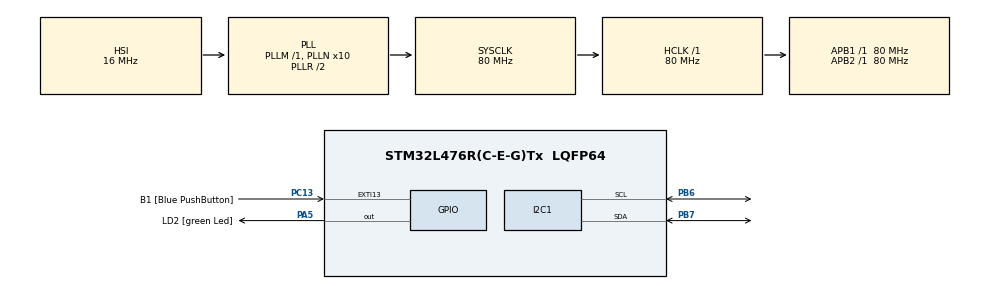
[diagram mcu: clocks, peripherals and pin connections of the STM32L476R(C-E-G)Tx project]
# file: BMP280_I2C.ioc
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I2C1.Timing=0x10D19CE4
Mcu.Family=STM32L4
Mcu.Name=STM32L476R(C-E-G)Tx
Mcu.Package=LQFP64
NVIC.PriorityGroup=NVIC_PRIORITYGROUP_4
PA13\ (JTMS-SWDIO).GPIO_Label=TMS
PA13\ (JTMS-SWDIO).Mode=Serial_Wire
PA13\ (JTMS-SWDIO).Signal=SYS_JTMS-SWDIO
PA14\ (JTCK-SWCLK).GPIO_Label=TCK
PA14\ (JTCK-SWCLK).Mode=Serial_Wire
PA14\ (JTCK-SWCLK).Signal=SYS_JTCK-SWCLK
PA5.GPIO_Label=LD2 [green Led]
PA5.GPIO_ModeDefaultOutputPP=GPIO_MODE_OUTPUT_PP
PA5.GPIO_PuPd=GPIO_NOPULL
PA5.GPIO_Speed=GPIO_SPEED_FREQ_LOW
PA5.Signal=GPIO_Output
PB3\ (JTDO-TRACESWO).GPIO_Label=SWO
PB3\ (JTDO-TRACESWO).Signal=SYS_JTDO-SWO
PB6.Mode=I2C
PB6.Signal=I2C1_SCL
PB7.Mode=I2C
PB7.Signal=I2C1_SDA
PC13.GPIO_Label=B1 [Blue PushButton]
PC13.GPIO_ModeDefaultEXTI=GPIO_MODE_IT_FALLING
PC13.GPIO_PuPd=GPIO_NOPULL
PC13.Signal=GPXTI13
PC14-OSC32_IN\ (PC14).Mode=LSE-External-Oscillator
PC14-OSC32_IN\ (PC14).Signal=RCC_OSC32_IN
PC15-OSC32_OUT\ (PC15).Mode=LSE-External-Oscillator
PC15-OSC32_OUT\ (PC15).Signal=RCC_OSC32_OUT
PH0-OSC_IN\ (PH0).Signal=RCC_OSC_IN
PH1-OSC_OUT\ (PH1).Signal=RCC_OSC_OUT
ProjectManager.HeapSize=0x200
ProjectManager.StackSize=0x400
ProjectManager.TargetToolchain=STM32CubeIDE
RCC.ADCFreq_Value=64000000
RCC.AHBFreq_Value=80000000
RCC.APB1Freq_Value=80000000
RCC.APB1TimFreq_Value=80000000
RCC.APB2Freq_Value=80000000
RCC.APB2TimFreq_Value=80000000
RCC.CortexFreq_Value=80000000
RCC.HCLKFreq_Value=80000000
RCC.HSE_VALUE=8000000
RCC.HSI_VALUE=16000000
RCC.MSI_VALUE=4000000
RCC.PLLN=10
RCC.PLLSourceVirtual=RCC_PLLSOURCE_HSI
RCC.PREFETCH_ENABLE=1
RCC.SYSCLKFreq_VALUE=80000000
RCC.SYSCLKSource=RCC_SYSCLKSOURCE_PLLCLK
RCC.USBFreq_Value=64000000
RCC.VCOOutputFreq_Value=160000000
board=NUCLEO-L476RG

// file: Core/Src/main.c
/* USER CODE BEGIN Header */
/**
  ******************************************************************************
  * @file           : main.c
  * @brief          : Main program body
  ******************************************************************************
  */
 /* USER CODE END Header */

#include "main.h"
#include "BMP280.h"

I2C_HandleTypeDef hi2c1;

void SystemClock_Config(void);
static void MX_GPIO_Init(void);
static void MX_I2C1_Init(void);

/* USER CODE BEGIN PV */
float temperature = 0.0f;
float pressure = 0.0f;
/* USER CODE END PV */

int main(void)
{
  HAL_Init();
  SystemClock_Config();

  MX_GPIO_Init();
  MX_I2C1_Init();

  /* USER CODE BEGIN 2 */
  if (BMP280_Config( BMP280_MODE_NORMAL, BMP280_OSRS_2, BMP280_OSRS_16, BMP280_T_SB_500, BMP280_FILTER_4) != 0)
  {
    Error_Handler(); // BMP280 init failed
  }
  /* USER CODE END 2 */

  while (1)
  {
    /* USER CODE BEGIN WHILE */
    if (BMP280_ReadSensor(&temperature, &pressure) == 0)
    {
        // temperature -> °C
        // pressure    -> hPa

        HAL_GPIO_TogglePin(LD2_GPIO_Port, LD2_Pin); // heartbeat LED
    }

    HAL_Delay(1000);
    /* USER CODE END WHILE */
  }
}

/* ======================= Peripheral Init ======================= */

void SystemClock_Config(void)
{
  RCC_OscInitTypeDef RCC_OscInitStruct = {0};
  RCC_ClkInitTypeDef RCC_ClkInitStruct = {0};

  HAL_PWREx_ControlVoltageScaling(PWR_REGULATOR_VOLTAGE_SCALE1);

  RCC_OscInitStruct.OscillatorType = RCC_OSCILLATORTYPE_HSI;
  RCC_OscInitStruct.HSIState = RCC_HSI_ON;
  RCC_OscInitStruct.PLL.PLLState = RCC_PLL_ON;
  RCC_OscInitStruct.PLL.PLLSource = RCC_PLLSOURCE_HSI;
  RCC_OscInitStruct.PLL.PLLM = 1;
  RCC_OscInitStruct.PLL.PLLN = 10;
  RCC_OscInitStruct.PLL.PLLR = RCC_PLLR_DIV2;

  HAL_RCC_OscConfig(&RCC_OscInitStruct);

  RCC_ClkInitStruct.ClockType =
      RCC_CLOCKTYPE_SYSCLK | RCC_CLOCKTYPE_HCLK |
      RCC_CLOCKTYPE_PCLK1 | RCC_CLOCKTYPE_PCLK2;

  RCC_ClkInitStruct.SYSCLKSource = RCC_SYSCLKSOURCE_PLLCLK;
  RCC_ClkInitStruct.AHBCLKDivider = RCC_SYSCLK_DIV1;
  RCC_ClkInitStruct.APB1CLKDivider = RCC_HCLK_DIV1;
  RCC_ClkInitStruct.APB2CLKDivider = RCC_HCLK_DIV1;

  HAL_RCC_ClockConfig(&RCC_ClkInitStruct, FLASH_LATENCY_4);
}

static void MX_I2C1_Init(void)
{
  hi2c1.Instance = I2C1;
  hi2c1.Init.Timing = 0x10D19CE4;
  hi2c1.Init.AddressingMode = I2C_ADDRESSINGMODE_7BIT;
  hi2c1.Init.OwnAddress1 = 0;
  hi2c1.Init.DualAddressMode = I2C_DUALADDRESS_DISABLE;
  hi2c1.Init.GeneralCallMode = I2C_GENERALCALL_DISABLE;
  hi2c1.Init.NoStretchMode = I2C_NOSTRETCH_DISABLE;

  HAL_I2C_Init(&hi2c1);
  HAL_I2CEx_ConfigAnalogFilter(&hi2c1, I2C_ANALOGFILTER_ENABLE);
}

static void MX_GPIO_Init(void)
{
  GPIO_InitTypeDef GPIO_InitStruct = {0};

  __HAL_RCC_GPIOA_CLK_ENABLE();
  __HAL_RCC_GPIOB_CLK_ENABLE();
  __HAL_RCC_GPIOC_CLK_ENABLE();

  GPIO_InitStruct.Pin = LD2_Pin;
  GPIO_InitStruct.Mode = GPIO_MODE_OUTPUT_PP;
  GPIO_InitStruct.Pull = GPIO_NOPULL;
  GPIO_InitStruct.Speed = GPIO_SPEED_FREQ_LOW;
  HAL_GPIO_Init(LD2_GPIO_Port, &GPIO_InitStruct);
}

/* ======================= Error Handler ======================= */

void Error_Handler(void)
{
  __disable_irq();
  while (1)
  {
  }
}
